# CC2753 register map
File version: 1.0
CPU: CM0+ r0p4, little endian, no MPU, no FPU, VTOR, 3 interrupt priority bits
Registers are 32-bit, read-write, reset 0x0 unless marked. A register's access mark holds for its fields unless they carry their own. Offsets are from the block's base; [hi:lo] are bit positions; 'fields as' and 'values as' point back to an identical list.

## PMCTL — This component is the Power Management controller. Together with the System Controller, it controls system resets and the power states of the device.
Base 0x40000000
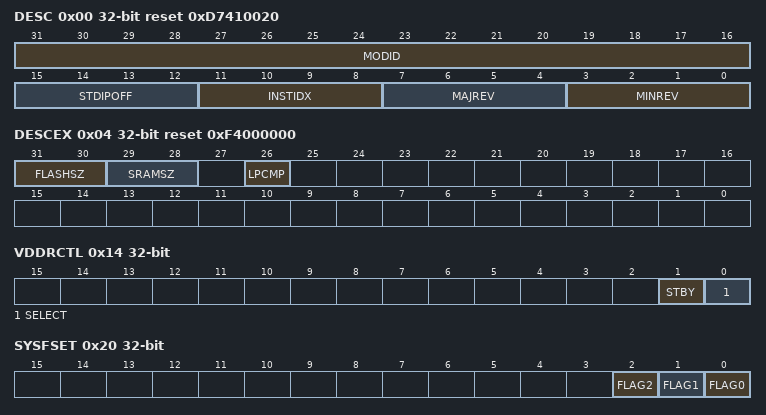
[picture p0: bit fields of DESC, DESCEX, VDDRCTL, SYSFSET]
0x00 DESC ro reset 0xD7410020 — Description Register. This register provides IP module ID, revision information, instance index and standard MMR registers offset.
  [31:16] MODID — Module identifier used to uniquely identify this IP.
  [15:12] STDIPOFF — Standard IP MMR block offset. Standard IP MMRs are the set of from aggregated IRQ registers till DTB. 0: Standard IP MMRs do not exist 0x1-0xF: Standard IP MMRs begin at offset of (64*STDIPOFF from the base IP address)
  [11:8] INSTIDX — IP Instance ID number. If multiple instances of IP exist in the device, this field can identify the instance number (0-15).
  [7:4] MAJREV — Major revision of IP (0-15).
  [3:0] MINREV — Minor revision of IP (0-15).
0x04 DESCEX ro reset 0xF4000000 — Extended Description Register. This register shows ULL IP availability and memory size configuration.
  [31:30] FLASHSZ — System flash availability
    3=SZ3 (Flash size set to level 3 (Max size)); 2=SZ2 (Flash size set to level 2); 1=SZ1 (Flash size set to level 1); 0=SZ0 (Flash size set to level 0 (Min size))
  [29:28] SRAMSZ — System SRAM availability
    3=SZ3 (SRAM size set to level 3 (Max size)); 2=SZ2 (SRAM size set to level 2); 1=SZ1 (SRAM size set to level 1); 0=SZ0 (SRAM size set to level 0 (Min size))
  [26] LPCMP — LPCMP (low power comparator) IP status on device
    1=IP_AVAIL (IP is available); 0=IP_UNAVAIL (IP is unavailable)
0x08 SHTDWN wo — Shutdown Register. This register controls SHUTDOWN mode entry.
  [15:0] KEY — Setting a valid key will trigger the device to enter SHUTDOWN mode.
    0xA5A5=VALID (This is the only valid key value that will trigger SHUTDOWN mode. All other values are invalid and will have no effect.)
0x0C SLPCTL — Sleep Control Register. This register controls I/O pad sleep mode. When I/O pad sleep mode is enabled all I/O pad outputs and I/O pad configurations are latched. Inputs are transparent if I/O pad is configured as input.
  [0] SLPN — The boot code will set this bit field and disable sleep mode, automatically unless waking up from a SHUTDOWN RSTSTA.SDDET is set. Application software must reconfigure the state for all IO's before setting this bit field upon waking up from a SHUTDOWN to avoid glitches on pins.
    1=DIS (I/O pad sleep mode is disabled); 0=EN (I/O pad sleep mode is enabled)
0x10 WUSTA ro reset 0x1 — Wakeup Status Register This register shows the device wakeup source. Used to distinguish between wakeup from STANDBY, SHUTDOWN and reset.
  [1:0] SRC — This field shows the device wakeup source.
    2=STBY (Wakeup from STANDBY mode.); 1=RST_SHTDWN (Wakeup from system reset / SHUTDOWN mode. See RSTSTA for more status information.)
0x14 VDDRCTL — VDDR Control Register. This register contains VDDR regulator settings for the device.
  [1] STBY — Select between continuous or duty-cycled VDDR regulation in STANDBY mode.
    1=PSUEDO (Continuous VDDR regulation in STANDBY mode.); 0=NORMAL (Duty-cycled VDDR regulation in STANDBY mode.)
  [0] SELECT — Select between GLDO and DCDC as VDDR regulator (in ACTIVE, IDLE and STANDBY mode).
    1=DCDC (DCDC enabled for regulation of VDDR voltage); 0=GLDO (GLDO enabled for regulation of VDDR voltage)
0x20 SYSFSET wo — Internal. Only to be used through TI provided API.
  [all] fields
    1=SET (Internal. Only to be used through TI provided API.); 0=NOEFF (Internal. Only to be used through TI provided API.)
  [2] FLAG2 — Internal. Only to be used through TI provided API.
  [1] FLAG1 — Internal. Only to be used through TI provided API.
  [0] FLAG0 — Internal. Only to be used through TI provided API.
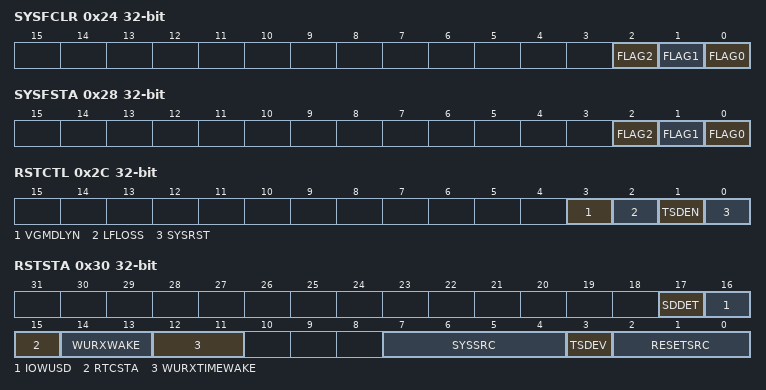
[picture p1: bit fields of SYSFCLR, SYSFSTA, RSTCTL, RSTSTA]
0x24 SYSFCLR wo — Internal. Only to be used through TI provided API.
  [all] fields
    1=CLR (Internal. Only to be used through TI provided API.); 0=NOEFF (Internal. Only to be used through TI provided API.)
  [2] FLAG2 — Internal. Only to be used through TI provided API.
  [1] FLAG1 — Internal. Only to be used through TI provided API.
  [0] FLAG0 — Internal. Only to be used through TI provided API.
0x28 SYSFSTA ro — Internal. Only to be used through TI provided API.
  [2] FLAG2 — Internal. Only to be used through TI provided API.
    1=Internal. Only to be used through TI provided API.; 0=Internal. Only to be used through TI provided API.
  [1] FLAG1 — Internal. Only to be used through TI provided API.
    1=Internal. Only to be used through TI provided API.
  [0] FLAG0 — Internal. Only to be used through TI provided API.
    values as FLAG2
0x2C RSTCTL — Reset Control Register. This register configures and controls system reset.
  [3] VGMDLYN — VDD glitch monitor delay. This bit configures if exit out of STANDBY will be stalled until VGM has settled or not. When bypassed the CPU execution will potentially start before the VGM is ready.
    1=DIS (VGM settling will not stall exit out of STANDBY.); 0=EN (Ensure that VGM has settled before we exit STANDBY.)
  [2] LFLOSS — LF clock loss reset enable. Trigger system reset when LF clock loss is detected, which reset the entire device and causes a reboot of the system. The system reset event is captured as RSTSTA.RESETSRC set to SYSRESET and RSTSTA.SYSSRC set to LFLOSSEV.
    1=ARMED (LF clock loss detection will trigger a system reset.); 0=DISARMED (LF clock loss detection will not trigger a system reset.)
  [1] TSDEN — TSD (Thermal Shutdown) enable. TSD will trigger an immediate system reset, which reset the entire device and causes a reboot of the system. The device will be in reset until released by the TSD IP. The system reset event is captured as RSTSTA.TSDEV flag set.
    1=EN (Temperature shutdown comparator enable. Note: If TSD IP not present, see DESCEX.TSD, enable will have no effect.); 0=NOEFF (No effect)
  [0] SYSRST — Trigger system reset, which will reset the entire device and causes a reboot of the system. The system reset event is captured as RSTSTA.RESETSRC set to SYSRESET and RSTSTA.SYSSRC set to SYSRSTEV.
    1=SET (Trigger a system reset.); 0=NOEFF (No effect)
0x30 RSTSTA ro — Reset Status. This register contains the reset source and SHUTDOWN wakeup source for the system. Check WUSTA.SRC first to ensure that wakeup from STANDBY is not set. The capture feature is not rearmed until all of the possible reset sources have been released and the result has been copied to this register. During the copy and rearm process it is one 24MHz period in which an eventual new system reset will be reported as Power on reset regardless of the root cause.
  [17] SDDET — Wakeup from SHUTDOWN flag. Note: This flag will be cleared when SLPCTL.SLPN is asserted.
    1=TRIG (Wakeup from SHUTDOWN mode); 0=NO_TRIG (Wakeup from SHUTDOWN mode not triggered.)
  [16] IOWUSD — Wakeup from SHUTDOWN on an I/O event flag. Note: This flag will be cleared when SLPCTL.SLPN is asserted.
    1=TRIG (Wakeup from SHUTDOWN triggered by an I/O event.); 0=NO_TRIG (Wakeup from SHUTDOWN not triggered by an I/O event.)
  [15] RTCSTA — RTC TIME reset status. This bit shows if the last system reset event cleared RTC TIME or not.
    1=NO_CLR (System reset event did not clear RTC TIME); 0=NO_TRIG (System reset event cleared RTC TIME)
  [14:13] WURXWAKE
    2=TRIG (Wakeup from shutdown triggered by WURX wake event.); 1=NO_TRIG (Wakeup from shutdown not triggered by WURX wake event.)
  [12:11] WURXTIMEWAKE
    2=TRIG (Wakeup from shutdown triggered by WURX timer event.); 1=NO_TRIG (Wakeup from shutdown not triggered by WURX timer event.)
  [7:4] SYSSRC — Shows which reset event that triggered SYSRESET in RESETSRC.
    15=DERREV (Digital Error reset event); 14=AERREV (Analog Error reset event); 9=SRAMEV (SRAM parity error event); 8=TAMPEREV (Tamper event); 7=EMSEV (Electromagnetic sensor event); 6=AFSMEV (Analog FSM timeout event); 5=SWDRSTEV (Serial Wire Debug reset event); 4=SYSRSTEV (System reset event); 3=WDTEV (Watchdog timeout event); 2=LOCKUPEV (CPU LOCKUP event); 1=CPURSTEV (CPU reset event); 0=LFLOSSEV (LF clock loss event)
  [3] TSDEV — System reset triggered by TSD event
    1=TRIG (System reset triggered by TSD event); 0=NO_TRIG (TSD event not triggered)
  [2:0] RESETSRC — Shows the root cause of the last system reset. More than one reported reset source can have been active during the last system reset, but only the root cause is reported. If reset cause is SYSRESET or PINRESET, the other reset flags must be read to determine actual root cause.
    7=VDDGLITCH (VDD glitch detection reset); 6=SYSRESET (Digital system reset. Actual root cause is given by SYSSRC.); 4=VDDRLOSS (Brown out detect on VDDR); 2=VDDSLOSS (Brown out detect on VDDS); 1=PINRESET (Reset pin. TSD will also trigger a pin reset, so actual root cause is given by TSDEV reset flag status.); 0=PWRON (Power on reset)
0x34 BOOTSTA — Internal. Only to be used through TI provided API.
  [7:0] FLAG
    255=APP_FAULT_HANDLER (Internal. Only to be used through TI provided API.); 254=APP_FAIL_APPTRANSFER (Internal. Only to be used through TI provided API.); 253=APP_FAIL_NOAPP (Internal. Only to be used through TI provided API.); 223=EM_SENSOR_CFG_FAIL (Internal. Only to be used through TI provided API.); 193=APP_WAITLOOP_DBGPROBE (Internal. Only to be used through TI provided API.); 192=MODE_APP (Internal. Only to be used through TI provided API.); 191=BLDR_FAULT_HANDLER (Internal. Only to be used through TI provided API.); 190=BLDR_FAIL_APPTRANSFER (Internal. Only to be used through TI provided API.); 189=BLDR_FAIL_EXECUTION_CONTEXT (Internal. Only to be used through TI provided API.); 188=BLDR_CMD_PROCESSING (Internal. Only to be used through TI provided API.); 187=BLDR_CMD_IDLE (Internal. Only to be used through TI provided API.); 186=BLDR_STARTED (Internal. Only to be used through TI provided API.); 129=BLDR_WAITLOOP_DBGPROBE (Internal. Only to be used through TI provided API.); 128=MODE_BLDR (Internal. Only to be used through TI provided API.); 63=BOOT_FAULT_HANDLER (Internal. Only to be used through TI provided API.); 62=BOOT_FAIL_SRAM_REPAIR (Internal. Only to be used through TI provided API.); 56=BOOT_WAITLOOP_DBGPROBE (Internal. Only to be used through TI provided API.); 55=BOOT_EXITED_SACI (Internal. Only to be used through TI provided API.); 54=BOOT_WAIT_SWD_DISCONNECT (Internal. Only to be used through TI provided API.); 53=BOOT_EXITED_SECURE_BOOT (Internal. Only to be used through TI provided API.); 52=BOOT_ENTERED_SECURE_BOOT (Internal. Only to be used through TI provided API.); 32=BOOT_ENTERED_SACI (Internal. Only to be used through TI provided API.); 3=BOOT_GENERAL_TRIMS (Internal. Only to be used through TI provided API.); 2=BOOT_SRAM_REP_DONE (Internal. Only to be used through TI provided API.); 1=BOOT_COLD_BOOT (Internal. Only to be used through TI provided API.); 0=BOOT_RESET (Internal. Only to be used through TI provided API.)
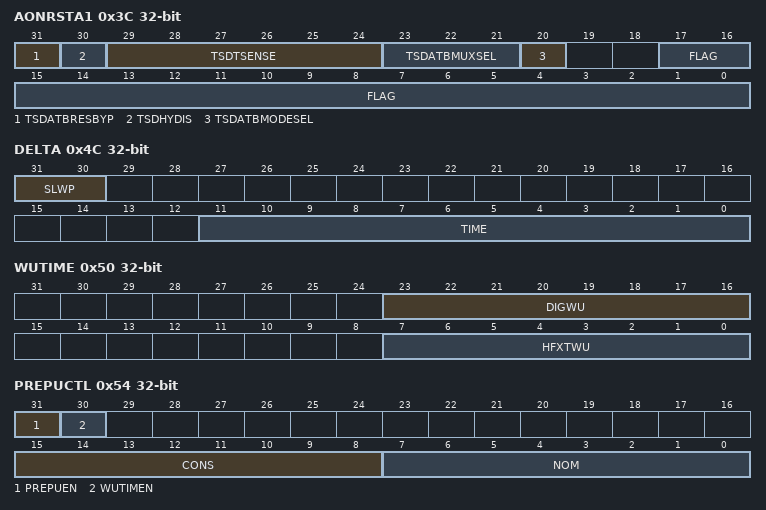
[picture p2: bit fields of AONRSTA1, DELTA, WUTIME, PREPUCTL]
0x3C AONRSTA1 ro — AON Register Status 1. This register contains the general purpose AON flags for SW, and is updated through AONRSET1.FLAG and AONRCLR1.FLAG. The register is only reset on a POR event.
  [31] TSDATBRESBYP — TSD ATB series resistor bypass
  [30] TSDHYDIS — TSD comparator hysteresis disable
  [29:24] TSDTSENSE — TSD comparator TSENSE trim
  [23:21] TSDATBMUXSEL — TSD comparator test multiplexer selection.
  [20] TSDATBMODESEL — TSD comparator test mode select.
  [17:0] FLAG — State of the AON register flags
0x40 AONRSET1 wo — AON Register Set 1. This register sets the AON flags that can be read through AONRSTA1.FLAG.
  [17:0] FLAG — Write 1 to set AONRSTA1.FLAG
    0x3FFFF=ALL_SET (Set all flags); 0=NOEFF (No flags changed status)
0x44 AONRCLR1 wo — AON register clear 1 Clear the AON flags that can be read through AONRSTA1.FLAG
  [17:0] FLAG — Write 1 to clear AONRSTA1.FLAG
    0x3FFFF=ALL_CLR (Clear all flags); 0=NOEFF (No flags changed status)
0x4C DELTA ro — Delta Time Register. This register contains the measured delta time during wakeup from STANDBY mode.
  [31:30] SLWP — Slow part. States which of HFXT ready or SW ready that completed first during wakeup from STANDBY mode.
    3=INVALID3 (No valid measurement available); 2=HFXT (HFXT ready set after SW ready (SWSTMP.SWRDY)); 1=SVT (HFXT ready set before SW ready (SWSTMP.SWRDY)); 0=INVALID0 (No valid measurement available)
  [11:0] TIME — Delta time. Measured time in us between SWSTMP.SWRDY and HFXT ready. This is a always a positive number, and SLWP is used to determine which event occurred first. Measurement is enabled when PREPUCTL.WUTIMEN is set.
0x50 WUTIME ro — WakeUp Time Register. This register contains the measured wakeup times from STANDBY mode.
  [23:16] DIGWU — Digital wakeup time. Gives the time (in us) from HFSOC is running until CPU execution starts. Measurement is enabled when PREPUCTL.WUTIMEN is set.
  [7:0] HFXTWU — HFXT wakeup time. Gives the time (in us) from HFSOC is running until HFXT auto enable is triggered. Measurement is enabled when PREPUCTL.WUTIMEN is set.
0x54 PREPUCTL — Pre Power-Up Control Register. This register contains settings and control for pre-powerup, STANDBY and wakeup measurements.
  [31] PREPUEN — Pre powerup Enable. When this bit is set, the device will start the wakeup process in advance of the RTC wakeup event. This to start HFXT settling earlier, so that HFXT can be ready when SW is ready. Note that HFXTCTL.AUTO must be enabled to turn on HFXT.
    1=EN (Enable pre-powerup); 0=DIS (Disable pre-powerup)
  [30] WUTIMEN — Wakeup time measurement enable. When set will enable WUTIME.DIGWU, WUTIME.HFXTWU and DELTA.TIME time measurements.
    1=EN (Enable wakeup time measurement); 0=DIS (Disable wakeup time measurement)
  [15:8] CONS — Conservative pre-wakeup time. When PREPUEN is set, the device will start the wakeup process in advance of the RTC wakeup event. This field will give the conservative time in advance of a RTC event. Conservative value is used if a temperature change has been detected since STANDBY mode was entered. The time unit for the value is 8us.
    254=MAX (Highest possible value); 0=MIN (Smallest value)
  [7:0] NOM — Nominal pre-wakeup time. When PREPUEN is set, the device will start the wakeup process in advance of the RTC wakeup event. This field will give the nominal time in advance of a RTC event. Nominal value is used if no temperature change has been detected since STANDBY mode was entered. The time unit for the value is 8us.
    254=MAX (Highest possible value); 0=MIN (Smallest value)
0x58 SWSTMP — SW Time Stamp Register. This register is used to set the SW time stamp for the delta time measurement.
  [0] SWRDY — SW ready. Set by SW to indicate when SW is ready. Used to measure DELTA.TIME and DELTA.SLWP. This bit is auto-cleared by HW.
    1=SET (Set SW ready time stamp. Auto-cleared by HW); 0=NOEFF (No effect)
0x64 ETPP — Internal. Only to be used through TI provided API.
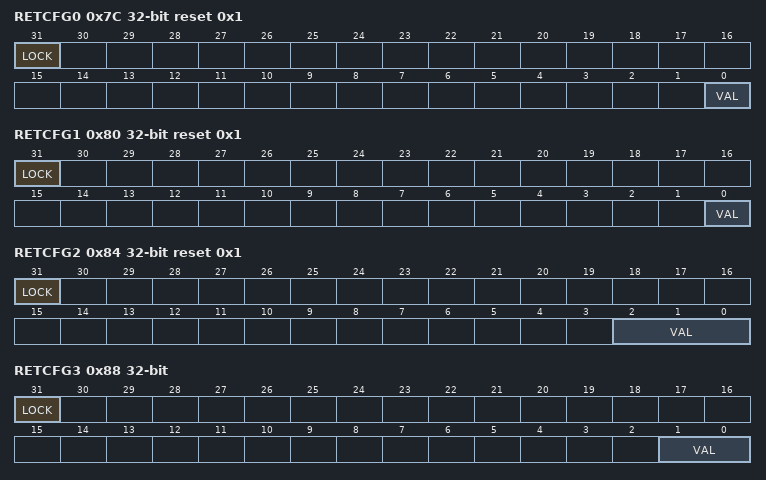
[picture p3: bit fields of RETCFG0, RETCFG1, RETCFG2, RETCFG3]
0x7C RETCFG0 reset 0x1 — Internal. Only to be used through TI provided API.
  [31] LOCK — Internal. Only to be used through TI provided API.
    1=SET (Internal. Only to be used through TI provided API.); 0=UNCHNG (Internal. Only to be used through TI provided API.)
  [0] VAL — Internal. Only to be used through TI provided API.
0x80 RETCFG1 reset 0x1 — Internal. Only to be used through TI provided API.
  fields as RETCFG0
0x84 RETCFG2 reset 0x1 — Internal. Only to be used through TI provided API.
  [31] LOCK — Internal. Only to be used through TI provided API.
    values as RETCFG0.LOCK
  [2:0] VAL — Internal. Only to be used through TI provided API.
0x88 RETCFG3 — Internal. Only to be used through TI provided API.
  [31] LOCK — Internal. Only to be used through TI provided API.
    values as RETCFG0.LOCK
  [1:0] VAL — Internal. Only to be used through TI provided API.
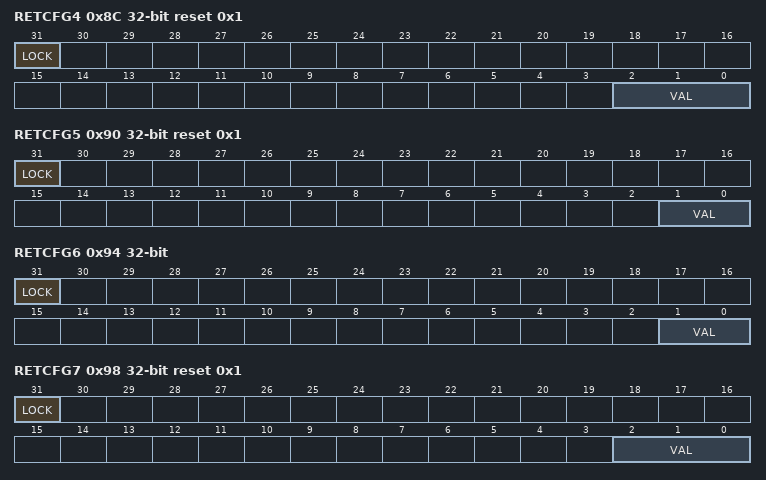
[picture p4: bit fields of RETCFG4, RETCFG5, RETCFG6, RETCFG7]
0x8C RETCFG4 reset 0x1 — Internal. Only to be used through TI provided API.
  fields as RETCFG2
0x90 RETCFG5 reset 0x1 — Internal. Only to be used through TI provided API.
  fields as RETCFG3
0x94 RETCFG6 — Internal. Only to be used through TI provided API.
  fields as RETCFG3
0x98 RETCFG7 reset 0x1 — Internal. Only to be used through TI provided API.
  fields as RETCFG2
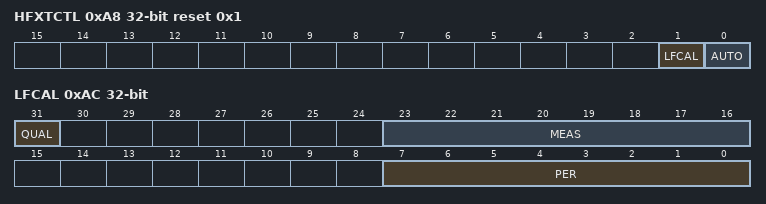
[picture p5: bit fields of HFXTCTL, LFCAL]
0xA8 HFXTCTL reset 0x1 — HFXT Control Register. This register controls features to turn on/off HFXT automatically.
  [1] LFCAL — LF Calibration Enable. Turn on/off HFXT periodically to perform LF oscillator calibration. LF oscillator period and measurement time is configured through LFCAL.
    1=EN (HFXT on/off periodically for LF calibration is enabled.); 0=DIS (HFXT on/off periodically for LF calibration is disabled.)
  [0] AUTO — Turn on/off HFXT during STANDBY entry/exit.
    1=EN (HFXT turned off when entring STANDBY and turned on when leaving STANDBY.); 0=DIS (HFXT is neither turned on/off during STANDBY entry/exit)
0xAC LFCAL — Low Frequency Calibration Register. This register contains the period and measurement time setting used for LF oscillator calibration. The LF calibartion feature is enabled through HFXTCTL.LFCAL.
  [31] QUAL — CKM qualifier configuration. Used to qualify that LF calibration is completed before HFXT is request off.
    1=EN (Enable CKM qualifier); 0=DIS (Disable CKM qualifier)
  [23:16] MEAS — LFCAL measurment time, given in number of 32kHz periods.
    255=MAX (Maximum LFCAL measurment time)
  [7:0] PER — LFCAL period time, given in number of 256 * 32kHz periods.
    255=MAX (Maximum LFCAL period time)
0xB0 VREFCFG reset 0x11 — Internal. Only to be used through TI provided API.
  [5:0] TIMEOUT
0xB4 VREFSTA ro — VREF Status Register. This register contains VREF settling status.
  [0] GOOD — VREF settling / good status.
    1=OK (VREF voltage is good.); 0=NOT_OK (VREF voltage is not good.)
